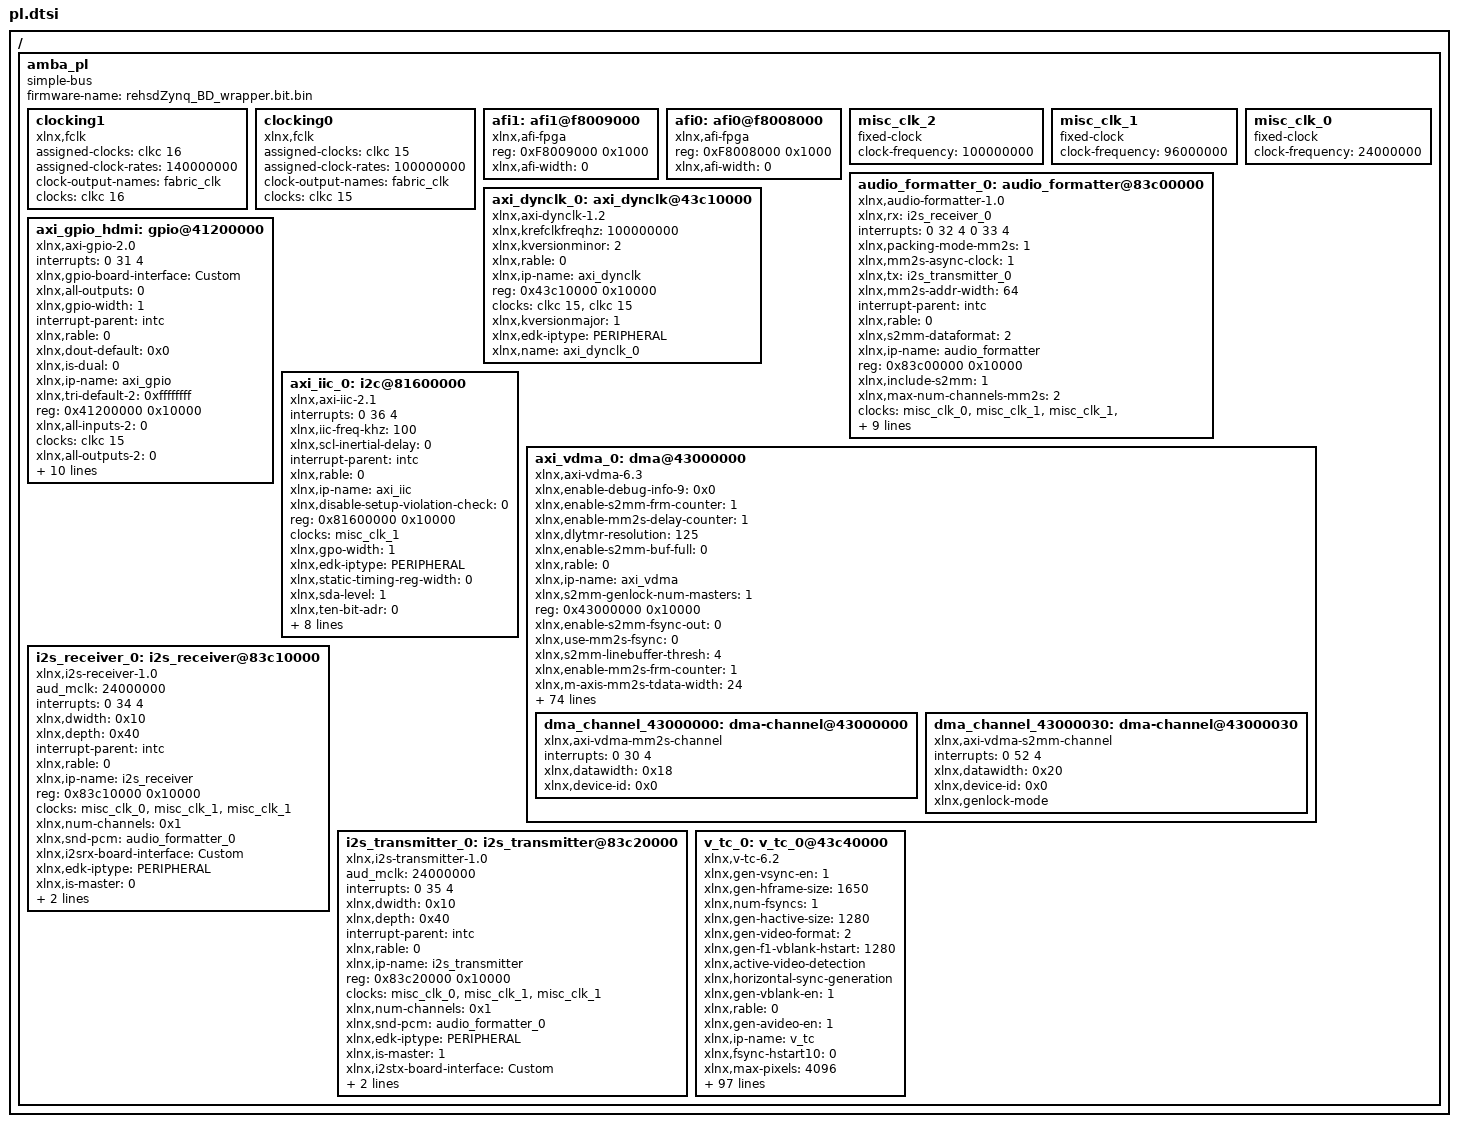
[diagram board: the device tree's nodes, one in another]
/ {
	amba_pl: amba_pl {
		ranges;
		compatible = "simple-bus";
		#address-cells = <1>;
		#size-cells = <1>;
		firmware-name = "rehsdZynq_BD_wrapper.bit.bin";
		clocking1: clocking1 {
			compatible = "xlnx,fclk";
			assigned-clocks = <&clkc 16>;
			assigned-clock-rates = <140000000>;
			#clock-cells = <0>;
			clock-output-names = "fabric_clk";
			clocks = <&clkc 16>;
		};
		clocking0: clocking0 {
			compatible = "xlnx,fclk";
			assigned-clocks = <&clkc 15>;
			assigned-clock-rates = <100000000>;
			#clock-cells = <0>;
			clock-output-names = "fabric_clk";
			clocks = <&clkc 15>;
		};
		afi1: afi1@f8009000 {
			status = "okay";
			compatible = "xlnx,afi-fpga";
			#address-cells = <1>;
			reg = <0xF8009000 0x1000>;
			#size-cells = <0>;
			xlnx,afi-width = <0>;
		};
		afi0: afi0@f8008000 {
			status = "okay";
			compatible = "xlnx,afi-fpga";
			#address-cells = <1>;
			reg = <0xF8008000 0x1000>;
			#size-cells = <0>;
			xlnx,afi-width = <0>;
		};
		misc_clk_2: misc_clk_2 {
			compatible = "fixed-clock";
			clock-frequency = <100000000>;
			#clock-cells = <0>;
		};
		misc_clk_1: misc_clk_1 {
			compatible = "fixed-clock";
			clock-frequency = <96000000>;
			#clock-cells = <0>;
		};
		misc_clk_0: misc_clk_0 {
			compatible = "fixed-clock";
			clock-frequency = <24000000>;
			#clock-cells = <0>;
		};
		audio_formatter_0: audio_formatter@83c00000 {
			xlnx,rx = <&i2s_receiver_0>;
			interrupts = < 0 32 4 0 33 4 >;
			compatible = "xlnx,audio-formatter-1.0" , "xlnx,audio-formatter-1.0";
			xlnx,packing-mode-mm2s = <1>;
			xlnx,mm2s-async-clock = <1>;
			xlnx,tx = <&i2s_transmitter_0>;
			xlnx,mm2s-addr-width = <64>;
			interrupt-parent = <&intc>;
			xlnx,rable = <0>;
			xlnx,s2mm-dataformat = <2>;
			xlnx,ip-name = "audio_formatter";
			reg = <0x83c00000 0x10000>;
			xlnx,include-s2mm = <1>;
			xlnx,max-num-channels-mm2s = <2>;
			clocks = <&misc_clk_0>, <&misc_clk_1>, <&misc_clk_1>, <&misc_clk_1>;
			xlnx,s2mm-async-clock = <1>;
			xlnx,packing-mode-s2mm = <1>;
			xlnx,edk-iptype = "PERIPHERAL";
			xlnx,s2mm-addr-width = <64>;
			status = "okay";
			clock-names = "aud_mclk" , "m_axis_mm2s_aclk" , "s_axi_lite_aclk" , "s_axis_s2mm_aclk";
			xlnx,mm2s-dataformat = <2>;
			interrupt-names = "irq_mm2s" , "irq_s2mm";
			xlnx,include-mm2s = <1>;
			xlnx,max-num-channels-s2mm = <2>;
			xlnx,name = "audio_formatter_0";
		};
		axi_dynclk_0: axi_dynclk@43c10000 {
			compatible = "xlnx,axi-dynclk-1.2";
			xlnx,krefclkfreqhz = <100000000>;
			xlnx,kversionminor = <2>;
			xlnx,rable = <0>;
			xlnx,ip-name = "axi_dynclk";
			reg = <0x43c10000 0x10000>;
			clocks = <&clkc 15>, <&clkc 15>;
			xlnx,kversionmajor = <1>;
			xlnx,edk-iptype = "PERIPHERAL";
			status = "okay";
			clock-names = "REF_CLK_I" , "s_axi_lite_aclk";
			xlnx,name = "axi_dynclk_0";
		};
		axi_gpio_hdmi: gpio@41200000 {
			#interrupt-cells = <2>;
			interrupts = < 0 31 4 >;
			xlnx,gpio-board-interface = "Custom";
			compatible = "xlnx,axi-gpio-2.0" , "xlnx,xps-gpio-1.00.a";
			xlnx,all-outputs = <0>;
			#gpio-cells = <2>;
			xlnx,gpio-width = <1>;
			interrupt-parent = <&intc>;
			xlnx,rable = <0>;
			xlnx,dout-default = <0x0>;
			xlnx,is-dual = <0>;
			xlnx,ip-name = "axi_gpio";
			xlnx,tri-default-2 = <0xffffffff>;
			reg = <0x41200000 0x10000>;
			xlnx,all-inputs-2 = <0>;
			clocks = <&clkc 15>;
			xlnx,all-outputs-2 = <0>;
			gpio-controller;
			xlnx,interrupt-present = <1>;
			xlnx,gpio2-board-interface = "Custom";
			xlnx,edk-iptype = "PERIPHERAL";
			xlnx,dout-default-2 = <0x0>;
			status = "okay";
			xlnx,gpio2-width = <32>;
			clock-names = "s_axi_aclk";
			interrupt-controller;
			interrupt-names = "ip2intc_irpt";
			xlnx,tri-default = <0xffffffff>;
			xlnx,name = "axi_gpio_hdmi";
			xlnx,all-inputs = <1>;
		};
		axi_iic_0: i2c@81600000 {
			interrupts = < 0 36 4 >;
			xlnx,iic-freq-khz = <100>;
			compatible = "xlnx,axi-iic-2.1" , "xlnx,xps-iic-2.00.a";
			xlnx,scl-inertial-delay = <0>;
			interrupt-parent = <&intc>;
			xlnx,rable = <0>;
			xlnx,ip-name = "axi_iic";
			xlnx,disable-setup-violation-check = <0>;
			reg = <0x81600000 0x10000>;
			clocks = <&misc_clk_1>;
			xlnx,gpo-width = <1>;
			xlnx,edk-iptype = "PERIPHERAL";
			xlnx,static-timing-reg-width = <0>;
			xlnx,sda-level = <1>;
			status = "okay";
			clock-names = "s_axi_aclk";
			xlnx,ten-bit-adr = <0>;
			xlnx,default-value = <0x0>;
			interrupt-names = "iic2intc_irpt";
			xlnx,iic-board-interface = "Custom";
			xlnx,timing-reg-width = <32>;
			xlnx,iic-freq = <100000>;
			xlnx,smbus-pmbus-host = <0>;
			xlnx,name = "axi_iic_0";
			xlnx,axi-aclk-freq-mhz = <96>;
			xlnx,sda-inertial-delay = <0>;
		};
		axi_vdma_0: dma@43000000 {
			xlnx,enable-debug-info-9 = <0x0>;
			xlnx,enable-s2mm-frm-counter = <1>;
			xlnx,enable-mm2s-delay-counter = <1>;
			xlnx,dlytmr-resolution = <125>;
			xlnx,enable-s2mm-buf-full = <0>;
			xlnx,rable = <0>;
			xlnx,ip-name = "axi_vdma";
			xlnx,s2mm-genlock-num-masters = <1>;
			reg = <0x43000000 0x10000>;
			xlnx,enable-s2mm-fsync-out = <0>;
			xlnx,use-mm2s-fsync = <0>;
			xlnx,s2mm-linebuffer-thresh = <4>;
			xlnx,enable-mm2s-frm-counter = <1>;
			xlnx,m-axis-mm2s-tdata-width = <24>;
			xlnx,enable-all = <0>;
			xlnx,dynamic-resolution = <1>;
			xlnx,enable-s2mm-rst-out = <0>;
			interrupt-names = "mm2s_introut" , "s2mm_introut";
			xlnx,s2mm-sof-enable = <0x1>;
			xlnx,mm2s-genlock-num-masters = <1>;
			xlnx,enable-mm2s-fsync-out = <0>;
			xlnx,mm2s-linebuffer-thresh = <4>;
			compatible = "xlnx,axi-vdma-6.3" , "xlnx,axi-vdma-1.00.a";
			xlnx,enable-tstvec = <0>;
			interrupt-parent = <&intc>;
			xlnx,s2mm-max-burst-length = <8>;
			xlnx,enable-mm2s-rst-out = <0>;
			xlnx,mm2s-sof-enable = <1>;
			xlnx,include-s2mm-dre = <0x0>;
			xlnx,enable-s2mm-frmstr-reg = <0>;
			xlnx,m-axi-s2mm-data-width = <64>;
			xlnx,enable-s2mm-sts-reg = <0>;
			xlnx,mm2s-max-burst-length = <8>;
			status = "okay";
			xlnx,include-mm2s-dre = <0x0>;
			xlnx,name = "axi_vdma_0";
			xlnx,enable-mm2s-frmstr-reg = <0>;
			interrupts = < 0 30 4 0 52 4 >;
			xlnx,m-axi-mm2s-data-width = <64>;
			xlnx,flush-on-fsync = <0x1>;
			xlnx,include-s2mm-sf = <1>;
			xlnx,single-interface = <0>;
			xlnx,s2mm-linebuffer-depth = <0x200>;
			xlnx,include-s2mm = <0x1>;
			xlnx,addr-width = <32>;
			clocks = <&clkc 16>, <&clkc 15>, <&clkc 16>, <&clkc 15>, <&clkc 15>;
			xlnx,s-axis-s2mm-tdata-width = <32>;
			xlnx,enable-debug-info-10 = <0>;
			xlnx,addrwidth = <0x20>;
			xlnx,enable-debug-info-11 = <0>;
			xlnx,edk-iptype = "PERIPHERAL";
			xlnx,enable-debug-info-12 = <0>;
			xlnx,use-fsync = <1>;
			xlnx,s2mm-genlock-repeat-en = <1>;
			xlnx,enable-debug-info-13 = <0x0>;
			xlnx,enable-vert-flip = <0x0>;
			xlnx,include-mm2s-sf = <0>;
			xlnx,enable-debug-info-14 = <0x1>;
			xlnx,include-internal-genlock = <0x1>;
			clock-names = "m_axi_mm2s_aclk" , "m_axi_s2mm_aclk" , "m_axis_mm2s_aclk" , "s_axi_lite_aclk" , "s_axis_s2mm_aclk";
			xlnx,enable-debug-info-15 = <0x1>;
			xlnx,mm2s-linebuffer-depth = <0x200>;
			xlnx,include-mm2s = <0x1>;
			xlnx,s2mm-genlock-mode = <0x2>;
			xlnx,flush-fsync = <0x1>;
			xlnx,select-xpm = <0>;
			xlnx,s2mm-data-width = <0x40>;
			xlnx,num-fstores = <0x4>;
			xlnx,enable-s2mm-param-updt = <0>;
			xlnx,enable-vidparam-reads = <0x1>;
			xlnx,mm2s-genlock-repeat-en = <0>;
			xlnx,prmry-is-aclk-async = <1>;
			xlnx,s2mm-tdata-width = <0x20>;
			#dma-cells = <1>;
			xlnx,enable-vidprmtr-reads = <1>;
			xlnx,mm2s-genlock-mode = <0x0>;
			xlnx,enable-debug-info-0 = <0>;
			xlnx,enable-debug-all = <0x0>;
			xlnx,enable-debug-info-1 = <0x0>;
			xlnx,mm2s-data-width = <0x40>;
			xlnx,enable-debug-info-2 = <0>;
			xlnx,enable-mm2s-param-updt = <0>;
			xlnx,enable-debug-info-3 = <0>;
			xlnx,enable-s2mm-delay-counter = <1>;
			xlnx,enable-debug-info-4 = <0>;
			xlnx,enable-debug-info-5 = <0x0>;
			xlnx,mm2s-tdata-width = <0x18>;
			xlnx,enable-debug-info-6 = <0x1>;
			xlnx,enable-debug-info-7 = <0x1>;
			xlnx,use-s2mm-fsync = <2>;
			xlnx,enable-debug-info-8 = <0>;
			xlnx,enable-mm2s-buf-empty = <0>;
			dma_channel_43000000: dma-channel@43000000 {
				interrupts = < 0 30 4 >;
				xlnx,datawidth = <0x18>;
				xlnx,device-id = <0x0>;
				compatible = "xlnx,axi-vdma-mm2s-channel";
			};
			dma_channel_43000030: dma-channel@43000030 {
				interrupts = < 0 52 4 >;
				xlnx,datawidth = <0x20>;
				xlnx,device-id = <0x0>;
				compatible = "xlnx,axi-vdma-s2mm-channel";
				xlnx,genlock-mode;
			};
		};
		i2s_receiver_0: i2s_receiver@83c10000 {
			aud_mclk = <24000000>;
			interrupts = < 0 34 4 >;
			compatible = "xlnx,i2s-receiver-1.0" , "xlnx,i2s-receiver-1.0";
			xlnx,dwidth = <0x10>;
			xlnx,depth = <0x40>;
			interrupt-parent = <&intc>;
			xlnx,rable = <0>;
			xlnx,ip-name = "i2s_receiver";
			reg = <0x83c10000 0x10000>;
			clocks = <&misc_clk_0>, <&misc_clk_1>, <&misc_clk_1>;
			xlnx,num-channels = <0x1>;
			xlnx,snd-pcm = <&audio_formatter_0>;
			xlnx,i2srx-board-interface = "Custom";
			xlnx,edk-iptype = "PERIPHERAL";
			xlnx,is-master = <0>;
			status = "okay";
			clock-names = "aud_mclk" , "m_axis_aud_aclk" , "s_axi_ctrl_aclk";
			xlnx,32bit-lr = <0>;
			interrupt-names = "irq";
			xlnx,name = "i2s_receiver_0";
		};
		i2s_transmitter_0: i2s_transmitter@83c20000 {
			aud_mclk = <24000000>;
			interrupts = < 0 35 4 >;
			compatible = "xlnx,i2s-transmitter-1.0" , "xlnx,i2s-transmitter-1.0";
			xlnx,dwidth = <0x10>;
			xlnx,depth = <0x40>;
			interrupt-parent = <&intc>;
			xlnx,rable = <0>;
			xlnx,ip-name = "i2s_transmitter";
			reg = <0x83c20000 0x10000>;
			clocks = <&misc_clk_0>, <&misc_clk_1>, <&misc_clk_1>;
			xlnx,num-channels = <0x1>;
			xlnx,snd-pcm = <&audio_formatter_0>;
			xlnx,edk-iptype = "PERIPHERAL";
			xlnx,is-master = <1>;
			xlnx,i2stx-board-interface = "Custom";
			status = "okay";
			clock-names = "aud_mclk" , "s_axi_ctrl_aclk" , "s_axis_aud_aclk";
			xlnx,32bit-lr = <0>;
			interrupt-names = "irq";
			xlnx,name = "i2s_transmitter_0";
		};
		v_tc_0: v_tc_0@43c40000 {
			xlnx,gen-vsync-en = <1>;
			xlnx,gen-hframe-size = <1650>;
			xlnx,num-fsyncs = <1>;
			xlnx,gen-hactive-size = <1280>;
			xlnx,gen-video-format = <2>;
			xlnx,gen-f1-vblank-hstart = <1280>;
			xlnx,active-video-detection;
			xlnx,horizontal-sync-generation;
			xlnx,gen-vblank-en = <1>;
			xlnx,rable = <0>;
			xlnx,gen-avideo-en = <1>;
			xlnx,ip-name = "v_tc";
			xlnx,fsync-hstart10 = <0>;
			xlnx,max-pixels = <4096>;
			xlnx,gen-fieldid-en = <0>;
			reg = <0x43c40000 0x10000>;
			xlnx,det-vblank-en = <1>;
			xlnx,fsync-hstart11 = <0>;
			xlnx,fsync-hstart12 = <0>;
			xlnx,gen-interlaced = <0>;
			xlnx,det-avideo-en = <1>;
			xlnx,fsync-hstart13 = <0>;
			xlnx,fsync-hstart14 = <0>;
			xlnx,gen-f0-vblank-hend = <1280>;
			xlnx,fsync-hstart15 = <0>;
			xlnx,det-hsync-en = <1>;
			interrupt-names = "irq";
			xlnx,enable-generation;
			xlnx,gen-avideo-polarity = <1>;
			xlnx,max-lines-per-frame = <4096>;
			xlnx,has-axi4-lite = <1>;
			compatible = "xlnx,v-tc-6.2" , "xlnx,v-tc-6.1" , "xlnx,bridge-v-tc-6.1";
			xlnx,max-clocks-per-line = <4096>;
			xlnx,gen-f0-vframe-size = <750>;
			xlnx,gen-f0-vblank-hstart = <1280>;
			interrupt-parent = <&intc>;
			xlnx,max-lines = <4096>;
			xlnx,gen-f0-vsync-vstart = <724>;
			xlnx,horizontal-blank-generation;
			xlnx,gen-hsync-end = <1430>;
			xlnx,gen-f0-vsync-hstart = <1280>;
			xlnx,gen-f1-vsync-hend = <1280>;
			xlnx,vertical-blank-detection;
			xlnx,gen-vsync-polarity = <1>;
			xlnx,fsync-vstart0 = <0>;
			xlnx,gen-hsync-polarity = <1>;
			xlnx,fsync-vstart1 = <0>;
			status = "okay";
			xlnx,fsync-vstart2 = <0>;
			xlnx,gen-hsync-start = <1390>;
			xlnx,gen-f0-vsync-vend = <729>;
			xlnx,fsync-vstart3 = <0>;
			xlnx,vertical-sync-detection;
			xlnx,frame-syncs = <1>;
			xlnx,fsync-vstart4 = <0>;
			xlnx,gen-vactive-size = <720>;
			xlnx,name = "v_tc_0";
			xlnx,fsync-vstart5 = <0>;
			interrupts = < 0 29 4 >;
			xlnx,gen-achroma-en = <0>;
			xlnx,fsync-vstart6 = <0>;
			xlnx,det-fieldid-en = <0>;
			xlnx,fsync-vstart7 = <0>;
			xlnx,gen-hsync-en = <1>;
			xlnx,fsync-vstart8 = <0>;
			xlnx,fsync-vstart10 = <0>;
			xlnx,fsync-vstart9 = <0>;
			xlnx,fsync-vstart11 = <0>;
			xlnx,arbitrary-res-en = <0>;
			xlnx,fsync-vstart12 = <0>;
			xlnx,fsync-vstart13 = <0>;
			clocks = <&misc_clk_2>, <&clkc 15>;
			xlnx,fsync-vstart14 = <0>;
			xlnx,fsync-vstart15 = <0>;
			xlnx,gen-cparity = <0>;
			xlnx,edk-iptype = "PERIPHERAL";
			xlnx,vertical-sync-generation;
			xlnx,gen-f1-vblank-hend = <1280>;
			xlnx,det-vsync-en = <1>;
			xlnx,gen-vblank-polarity = <1>;
			xlnx,fsync-hstart0 = <0>;
			clock-names = "clk" , "s_axi_aclk";
			xlnx,interlace-en = <0>;
			xlnx,gen-auto-switch = <0>;
			xlnx,fsync-hstart1 = <0>;
			xlnx,fsync-hstart2 = <0>;
			xlnx,active-video-generation;
			xlnx,fsync-hstart3 = <0>;
			xlnx,fsync-hstart4 = <0>;
			xlnx,horizontal-blank-detection;
			xlnx,fsync-hstart5 = <0>;
			xlnx,gen-f1-vframe-size = <750>;
			xlnx,fsync-hstart6 = <0>;
			xlnx,fsync-hstart7 = <0>;
			xlnx,fsync-hstart8 = <0>;
			xlnx,gen-hblank-en = <1>;
			xlnx,fsync-hstart9 = <0>;
			xlnx,horizontal-sync-detection;
			xlnx,gen-f1-vsync-vend = <729>;
			xlnx,detect-en = <0>;
			xlnx,det-hblank-en = <1>;
			xlnx,vid-ppc = <4>;
			xlnx,has-intc-if = <0>;
			xlnx,generate-en = <1>;
			xlnx,gen-achroma-polarity = <1>;
			xlnx,sync-en = <0>;
			xlnx,det-achroma-en = <0>;
			xlnx,generator;
			xlnx,gen-f1-vsync-vstart = <724>;
			xlnx,vertical-blank-generation;
			xlnx,gen-hblank-polarity = <1>;
			xlnx,video-mode = "720p";
			xlnx,gen-fieldid-polarity = <1>;
			xlnx,gen-f1-vsync-hstart = <1280>;
			xlnx,gen-f0-vsync-hend = <1280>;
		};
	};
};
